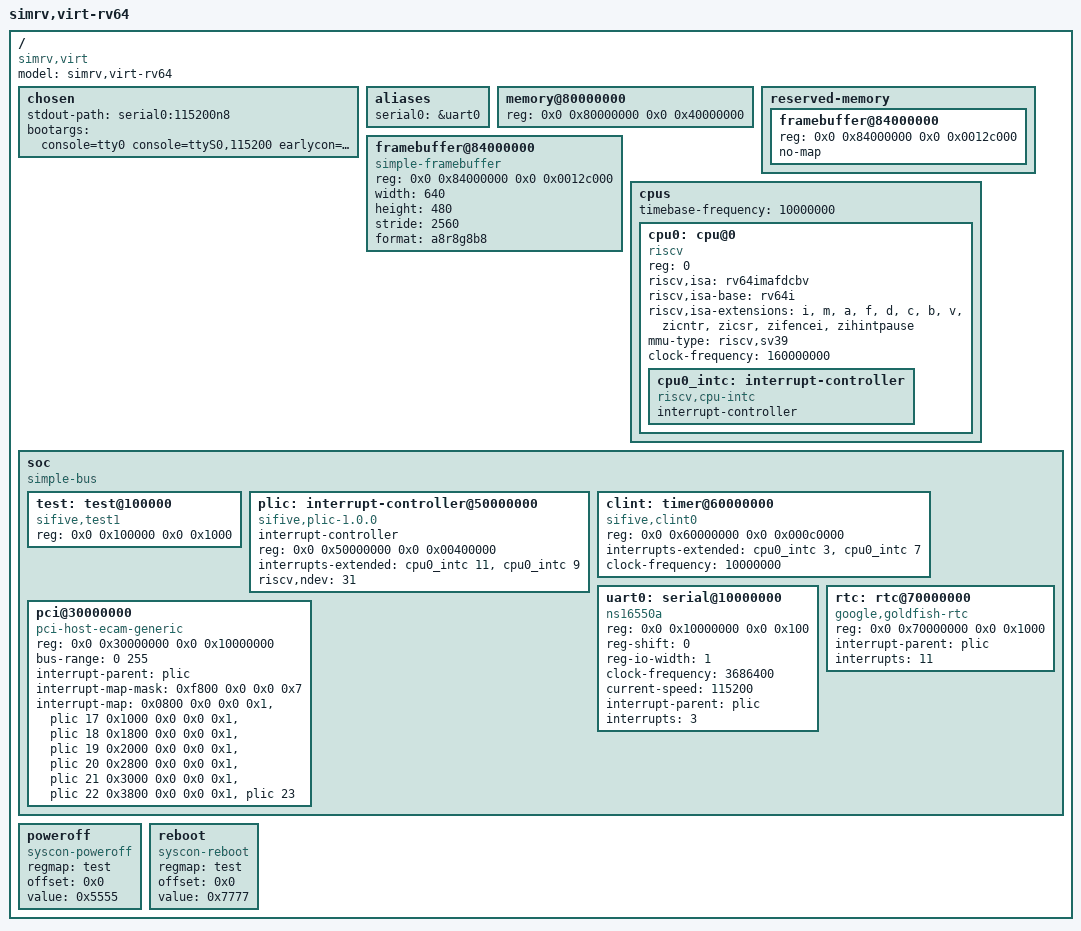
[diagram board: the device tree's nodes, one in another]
/dts-v1/;

/ {
    #address-cells = <2>;
    #size-cells = <2>;
    compatible = "simrv,virt";
    model = "simrv,virt-rv64";

    chosen {
        stdout-path = "serial0:115200n8";
        bootargs = "console=tty0 console=ttyS0,115200 earlycon=uart8250,mmio,0x10000000,115200n8 root=/dev/vda rw loglevel=7";
    };

    aliases {
        serial0 = &uart0;
    };

    memory@80000000 {
        device_type = "memory";
        reg = <0x0 0x80000000 0x0 0x40000000>;
    };

    reserved-memory {
        #address-cells = <2>;
        #size-cells = <2>;
        ranges;
        framebuffer@84000000 {
            reg = <0x0 0x84000000 0x0 0x0012c000>;
            no-map;
        };
    };

    framebuffer@84000000 {
        compatible = "simple-framebuffer";
        reg = <0x0 0x84000000 0x0 0x0012c000>;
        width = <640>;
        height = <480>;
        stride = <2560>;
        format = "a8r8g8b8";
    };

    cpus {
        #address-cells = <1>;
        #size-cells = <0>;
        timebase-frequency = <10000000>;

        cpu0: cpu@0 {
            compatible = "riscv";
            device_type = "cpu";
            reg = <0>;
            riscv,isa = "rv64imafdcbv";
            riscv,isa-base = "rv64i";
            riscv,isa-extensions = "i", "m", "a", "f", "d", "c", "b", "v", "zicntr", "zicsr", "zifencei", "zihintpause";
            mmu-type = "riscv,sv39";
            clock-frequency = <160000000>;

            cpu0_intc: interrupt-controller {
                #interrupt-cells = <1>;
                #address-cells = <0>;
                compatible = "riscv,cpu-intc";
                interrupt-controller;
            };
        };
    };

    soc {
        #address-cells = <2>;
        #size-cells = <2>;
        compatible = "simple-bus";
        ranges;

        test: test@100000 {
            compatible = "sifive,test1", "sifive,test0", "syscon";
            reg = <0x0 0x100000 0x0 0x1000>;
        };

        plic: interrupt-controller@50000000 {
            #address-cells = <0>;
            #interrupt-cells = <1>;
            compatible = "sifive,plic-1.0.0", "riscv,plic0";
            interrupt-controller;
            reg = <0x0 0x50000000 0x0 0x00400000>;
            interrupts-extended = <&cpu0_intc 11 &cpu0_intc 9>;
            riscv,ndev = <31>;
        };

        clint: timer@60000000 {
            compatible = "sifive,clint0", "riscv,clint0";
            reg = <0x0 0x60000000 0x0 0x000c0000>;
            interrupts-extended = <&cpu0_intc 3 &cpu0_intc 7>;
            clock-frequency = <10000000>;
        };

        uart0: serial@10000000 {
            compatible = "ns16550a";
            reg = <0x0 0x10000000 0x0 0x100>;
            reg-shift = <0>;
            reg-io-width = <1>;
            clock-frequency = <3686400>;
            current-speed = <115200>;
            interrupt-parent = <&plic>;
            interrupts = <3>;
        };

        pci@30000000 {
            compatible = "pci-host-ecam-generic";
            device_type = "pci";
            #address-cells = <3>;
            #size-cells = <2>;
            #interrupt-cells = <1>;
            reg = <0x0 0x30000000 0x0 0x10000000>;
            bus-range = <0 255>;
            ranges = <0x02000000 0x0 0x40000000 0x0 0x40000000 0x0 0x10000000>;
            interrupt-parent = <&plic>;
            interrupt-map-mask = <0xf800 0x0 0x0 0x7>;
            interrupt-map = <0x0800 0x0 0x0 0x1 &plic 17
                             0x1000 0x0 0x0 0x1 &plic 18
                             0x1800 0x0 0x0 0x1 &plic 19
                             0x2000 0x0 0x0 0x1 &plic 20
                             0x2800 0x0 0x0 0x1 &plic 21
                             0x3000 0x0 0x0 0x1 &plic 22
                             0x3800 0x0 0x0 0x1 &plic 23>;
        };

        rtc: rtc@70000000 {
            compatible = "google,goldfish-rtc";
            reg = <0x0 0x70000000 0x0 0x1000>;
            interrupt-parent = <&plic>;
            interrupts = <11>;
        };
    };

    poweroff {
        compatible = "syscon-poweroff";
        regmap = <&test>;
        offset = <0x0>;
        value = <0x5555>;
    };

    reboot {
        compatible = "syscon-reboot";
        regmap = <&test>;
        offset = <0x0>;
        value = <0x7777>;
    };
};
